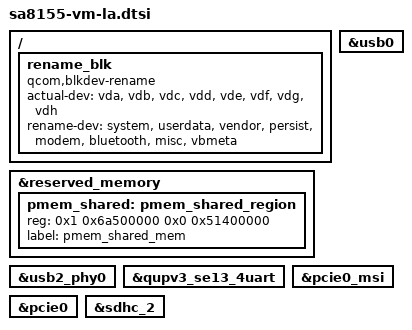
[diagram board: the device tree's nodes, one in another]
&reserved_memory {
	pmem_shared: pmem_shared_region {
		reg = <0x1 0x6a500000 0x0 0x51400000>;
		label = "pmem_shared_mem";
	};
};

/ {
	rename_blk: rename_blk {
		compatible = "qcom,blkdev-rename";
		actual-dev = "vda", "vdb", "vdc",
				"vdd", "vde", "vdf",
				"vdg", "vdh";
		rename-dev = "system", "userdata", "vendor",
				"persist", "modem", "bluetooth",
				"misc", "vbmeta";
	};
};
&usb0 {
	status = "ok";
};

&usb2_phy0 {
	status = "ok";
};

&qupv3_se13_4uart {
	status = "ok";
};

&pcie0_msi {
	status = "ok";
};

&pcie0 {
	status = "ok";
};

&sdhc_2 {
	status = "ok";
};
